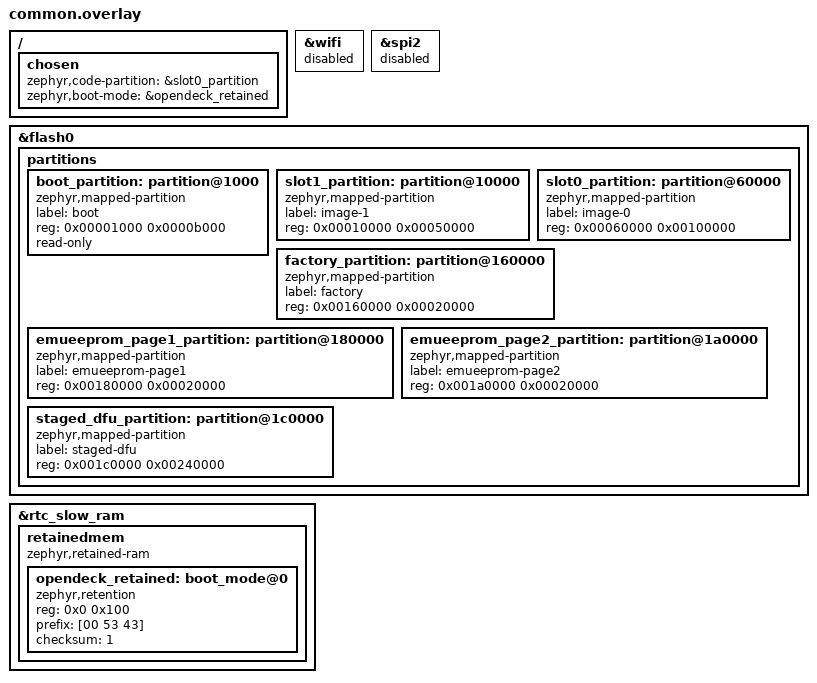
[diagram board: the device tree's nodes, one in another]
/ {
    chosen {
        /delete-property/ zephyr,canbus;
    };
};

&wifi {
    status = "disabled";
};

&spi2 {
    status = "disabled";
};

&flash0 {
    /delete-node/ partitions;

    partitions {
        #address-cells = <1>;
        #size-cells = <1>;

        boot_partition: partition@1000 {
            compatible = "zephyr,mapped-partition";
            label = "boot";
            reg = <0x00001000 0x0000b000>;
            read-only;
        };

        /*
         * image-1 is the OpenDeck bootloader; keep it before image-0 so merged images stay compact.
         * ESP32 mapped application images must start on 64 KiB boundaries.
         */
        slot1_partition: partition@10000 {
            compatible = "zephyr,mapped-partition";
            label = "image-1";
            reg = <0x00010000 0x00050000>;
        };

        slot0_partition: partition@60000 {
            compatible = "zephyr,mapped-partition";
            label = "image-0";
            reg = <0x00060000 0x00100000>;
        };

        factory_partition: partition@160000 {
            compatible = "zephyr,mapped-partition";
            label = "factory";
            reg = <0x00160000 0x00020000>;
        };

        emueeprom_page1_partition: partition@180000 {
            compatible = "zephyr,mapped-partition";
            label = "emueeprom-page1";
            reg = <0x00180000 0x00020000>;
        };

        emueeprom_page2_partition: partition@1a0000 {
            compatible = "zephyr,mapped-partition";
            label = "emueeprom-page2";
            reg = <0x001a0000 0x00020000>;
        };

        staged_dfu_partition: partition@1c0000 {
            compatible = "zephyr,mapped-partition";
            label = "staged-dfu";
            reg = <0x001c0000 0x00240000>;
        };
    };
};

/ {
    chosen {
        zephyr,code-partition = &slot0_partition;
        zephyr,boot-mode = &opendeck_retained;
    };
};

&rtc_slow_ram {
    status = "okay";
    #address-cells = <1>;
    #size-cells = <1>;

    retainedmem {
        compatible = "zephyr,retained-ram";
        status = "okay";
        #address-cells = <1>;
        #size-cells = <1>;

        opendeck_retained: boot_mode@0 {
            compatible = "zephyr,retention";
            status = "okay";
            reg = <0x0 0x100>;
            prefix = [00 53 43];
            checksum = <1>;
        };
    };
};
